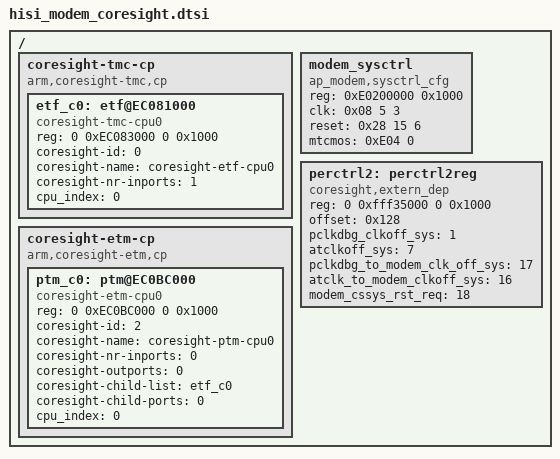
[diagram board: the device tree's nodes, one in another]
/*
 * Hisilicon Ltd Balong SOC
 */

/include/ "skeleton.dtsi"

/{
	coresight-tmc-cp {
		compatible = "arm,coresight-tmc,cp";
		ranges;
		/*tmc cpu 0*/
		etf_c0: etf@EC081000 {
			compatible = "coresight-tmc-cpu0";
			reg = <0 0xEC083000 0 0x1000>;
			
			coresight-id = <0>;
			coresight-name = "coresight-etf-cpu0";
			coresight-nr-inports = <1>;
			cpu_index = <0>;
		};		
	};
	coresight-etm-cp {
		compatible = "arm,coresight-etm,cp";
		ranges;
		/*etm cpu0*/
		ptm_c0: ptm@EC0BC000 {
			compatible = "coresight-etm-cpu0";
			reg = <0 0xEC0BC000 0 0x1000>;
			
			coresight-id = <2>;
			coresight-name = "coresight-ptm-cpu0";
			coresight-nr-inports = <0>;
			coresight-outports = <0>;
			coresight-child-list = <&etf_c0>;
			coresight-child-ports = <0>;
			cpu_index = <0>;
		};		
	};
	modem_sysctrl:modem_sysctrl {
		compatible = "ap_modem,sysctrl_cfg";
		reg = <0xE0200000 0x1000>;
		clk = <0x08 5 3>;
		reset =<0x28 15 6>;
		mtcmos =<0xE04 0>;
	};
   	perctrl2:perctrl2reg{
		compatible = "coresight,extern_dep";
        reg = <0 0xfff35000 0 0x1000>;
		offset = <0x128>;
		pclkdbg_clkoff_sys = <1>;           
        atclkoff_sys= <7>;                 
        pclkdbg_to_modem_clk_off_sys = <17>; 
        atclk_to_modem_clkoff_sys = <16>;    
        modem_cssys_rst_req = <18>;          

	};
};
